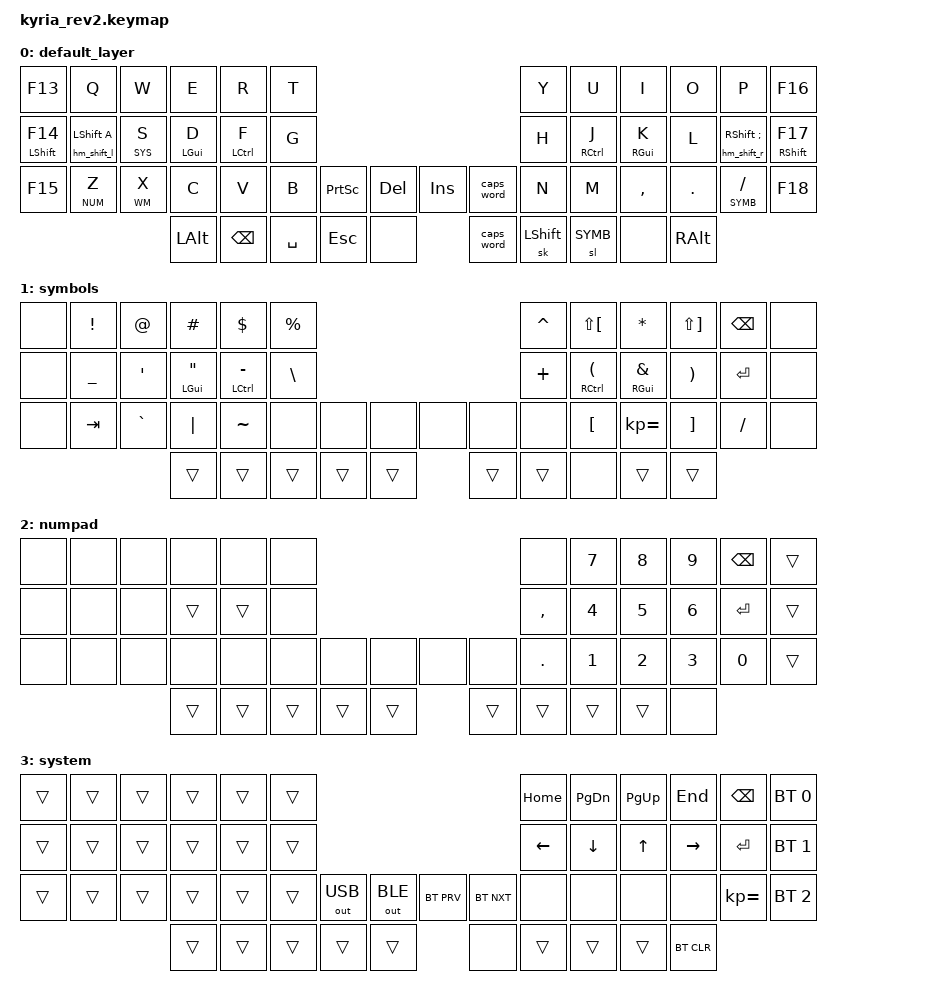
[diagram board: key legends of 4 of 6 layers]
/*
 * Copyright (c) 2020 The ZMK Contributors
 *
 * SPDX-License-Identifier: MIT
 */

#include "../zmk-nodefree-config/helper.h"
#include <behaviors.dtsi>
#include <dt-bindings/zmk/keys.h>
#include <dt-bindings/zmk/bt.h>
#include <dt-bindings/zmk/outputs.h>
#include "include/behaviours_homerow_mods.dtsi"


#define DEF 0
#define SYMB 1
#define NUM 2
#define SYS 3
#define WM 4
#define BLANK 5

&mt {
    flavor = "hold-preferred";
    tapping-term-ms = <150>;
};

&lt {
    flavor = "balanced";
    tapping-term-ms = <150>;
};

&sl {
    release-after-ms = <250>;
};

// / {
//     macros {
//         exit_symbol: exit_symbol {
//             label = "ZM_zed_em_kay";
//             compatible = "zmk,behavior-macro";
//             #binding-cells = <0>;
//             bindings = <&macro_tap &kp RETURN &to DEF>;
//         };
//         i3_1: i3_1 {
//             label = "ZM_zed_em_kay";
//             compatible = "zmk,behavior-macro";
//             #binding-cells = <0>;
//             bindings
//                 = <&macro_press &kp LGUI>
//                 , <&macro_tap &kp N1 >
//                 , <&macro_release &kp LGUI>
//                 ;
//         };
//         i3_2: i3_2 {
//             label = "ZM_zed_em_kay";
//             compatible = "zmk,behavior-macro";
//             #binding-cells = <0>;
//             bindings
//                 = <&macro_press &kp LGUI>
//                 , <&macro_tap &kp N2 >
//                 , <&macro_release &kp LGUI>
//                 ;
//         };
//         i3_3: i3_3 {
//             label = "ZM_zed_em_kay";
//             compatible = "zmk,behavior-macro";
//             #binding-cells = <0>;
//             bindings
//                 = <&macro_press &kp LGUI>
//                 , <&macro_tap &kp N3 >
//                 , <&macro_release &kp LGUI>
//                 ;
//         };
//         i3_4: i3_4 {
//             label = "ZM_zed_em_kay";
//             compatible = "zmk,behavior-macro";
//             #binding-cells = <0>;
//             bindings
//                 = <&macro_press &kp LGUI>
//                 , <&macro_tap &kp N4 >
//                 , <&macro_release &kp LGUI>
//                 ;
//         };
//         i3_5: i3_5 {
//             label = "ZM_zed_em_kay";
//             compatible = "zmk,behavior-macro";
//             #binding-cells = <0>;
//             bindings
//                 = <&macro_press &kp LGUI>
//                 , <&macro_tap &kp N5 >
//                 , <&macro_release &kp LGUI>
//                 ;
//         };
//         i3_6: i3_6 {
//             label = "ZM_zed_em_kay";
//             compatible = "zmk,behavior-macro";
//             #binding-cells = <0>;
//             bindings
//                 = <&macro_press &kp LGUI>
//                 , <&macro_tap &kp N6 >
//                 , <&macro_release &kp LGUI>
//                 ;
//         };
//         i3_7: i3_7 {
//             label = "ZM_zed_em_kay";
//             compatible = "zmk,behavior-macro";
//             #binding-cells = <0>;
//             bindings
//                 = <&macro_press &kp LGUI>
//                 , <&macro_tap &kp N7 >
//                 , <&macro_release &kp LGUI>
//                 ;
//         };
//         i3_8: i3_8 {
//             label = "ZM_zed_em_kay";
//             compatible = "zmk,behavior-macro";
//             #binding-cells = <0>;
//             bindings
//                 = <&macro_press &kp LGUI>
//                 , <&macro_tap &kp N8 >
//                 , <&macro_release &kp LGUI>
//                 ;
//         };
//         i3_9: i3_9 {
//             label = "ZM_zed_em_kay";
//             compatible = "zmk,behavior-macro";
//             #binding-cells = <0>;
//             bindings
//                 = <&macro_press &kp LGUI>
//                 , <&macro_tap &kp N9 >
//                 , <&macro_release &kp LGUI>
//                 ;
//         };
//     };
// };
//
// / {
//     combos {
//         compatible = "zmk,combos";
//         combo_caps_right {
//             timeout-ms = <50>;
//             key-positions = <20 21 22>;
//             bindings = <&caps_word>;
//         };
//         combo_caps_left {
//             timeout-ms = <50>;
//             key-positions = <14 15 16>;
//             bindings = <&caps_word>;
//         };
//         combo_i3_1 {
//             timeout-ms = <50>;
//             key-positions = <2 14>;
//             bindings = <&i3_1>;
//         };
//         combo_i3_2 {
//             timeout-ms = <50>;
//             key-positions = <3 15>;
//             bindings = <&i3_2>;
//         };
//         combo_i3_3 {
//             timeout-ms = <50>;
//             key-positions = <4 16>;
//             bindings = <&i3_3>;
//         };
//         combo_i3_4 {
//             timeout-ms = <50>;
//             key-positions = <14 26>;
//             bindings = <&i3_4>;
//         };
//         combo_i3_5 {
//             timeout-ms = <50>;
//             key-positions = <15 27>;
//             bindings = <&i3_5>;
//         };
//         combo_i3_6 {
//             timeout-ms = <50>;
//             key-positions = <16 28>;
//             bindings = <&i3_6>;
//         };
//         combo_i3_7 {
//             timeout-ms = <50>;
//             key-positions = <13 14>;
//             bindings = <&i3_7>;
//         };
//         combo_i3_8 {
//             timeout-ms = <50>;
//             key-positions = <14 15>;
//             bindings = <&i3_8>;
//         };
//         combo_i3_9 {
//             timeout-ms = <50>;
//             key-positions = <15 16>;
//             bindings = <&i3_9>;
//         };
//     };
// };

/ {
    
    

	keymap {
		compatible = "zmk,keymap";

		default_layer {
			bindings = <
&kp F13 &kp Q    &kp W    &kp E     &kp R     &kp T                                                    &kp Y      &kp U      &kp I     &kp O   &kp P    &kp F16
&mt LSHIFT F14 &hm_shift_l LSHFT A    &lt SYS S    &hm_l LGUI D    &hm_l LCTRL F     &kp G                        &kp H      &hm_r RCTRL J     &hm_r RGUI K    &kp L   &hm_shift_r RSHFT SEMI &mt RSHIFT F17
&kp F15 &lt NUM Z    &lt WM X    &kp C     &kp V     &kp B     &kp PSCRN &kp DEL        &kp INSERT &caps_word &kp N      &kp M      &kp COMMA &kp DOT &lt SYMB FSLH &kp F18
                        &kp LALT  &kp BSPC &kp SPACE &kp ESC &none       &caps_word &sk LSHIFT  &sl SYMB &none   &kp RALT
			>;
			sensor-bindings = <&inc_dec_kp C_VOL_UP C_VOL_DN &inc_dec_kp PG_UP PG_DN>;

		};

		symbols {
			bindings = <
&none &kp EXCL  &kp AT    &kp HASH &kp DOLLAR &kp PERCENT                                &kp CARET  &kp LS(LBKT) &kp STAR     &kp LS(RBKT) &kp BSPC   &none
&none &kp UNDER &kp SQT   &hm_l LGUI DQT  &hm_l LCTRL MINUS  &kp BSLH                                   &kp PLUS   &hm_r RCTRL LPAR     &hm RGUI AMPS     &kp RPAR     &kp RETURN &none
&none &kp TAB   &kp GRAVE &kp PIPE &kp TILDE  &none     &none &none     &none &none    &none      &kp LBKT     &kp KP_EQUAL &kp RBKT     &kp FSLH   &none
                          &trans    &trans      &trans   &trans &trans     &trans &trans &none &trans     &trans
			>;
			sensor-bindings = <&inc_dec_kp C_VOL_UP C_VOL_DN &inc_dec_kp PG_UP PG_DN>;
		};


		numpad {
			bindings = <
&none &none &none &none &none &none                              &none      &kp N7   &kp N8  &kp N9  &kp BSPC   &trans
&none &none &none &trans &trans &none                            &kp COMMA  &kp N4   &kp N5  &kp N6  &kp RETURN &trans
&none &none &none &none &none &none  &none &none     &none &none &kp DOT    &kp N1   &kp N2  &kp N3  &kp N0     &trans
                  &trans &trans &trans  &trans &trans     &trans &trans &trans    &trans  &none
			>;
			sensor-bindings = <&inc_dec_kp C_VOL_UP C_VOL_DN &inc_dec_kp PG_UP PG_DN>;
		};


		system {
			bindings = <
&trans  &trans &trans &trans  &trans  &trans                                                        &kp HOME   &kp PG_DN &kp PG_UP  &kp END   &kp BSPC    &bt BT_SEL 0
&trans  &trans &trans &trans  &trans  &trans                                                        &kp LEFT   &kp DOWN  &kp UP     &kp RIGHT &kp RETURN  &bt BT_SEL 1
&trans  &trans &trans &trans  &trans  &trans  &out OUT_USB  &out OUT_BLE      &bt BT_PRV  &bt BT_NXT &none     &none      &none     &none       &kp KP_EQUAL  &bt BT_SEL 2
                   &trans &trans &trans &trans        &trans     &none &trans &trans &trans     &bt BT_CLR
			>;
			sensor-bindings = <&inc_dec_kp C_VOL_UP C_VOL_DN &inc_dec_kp PG_UP PG_DN>;
		};

		wm {
			bindings = <
    &none &none &none &none &none &none                                &kp F1 &kp F2 &kp F3 &kp F4 &kp F5 &none
    &none &none &none &none &none &none                                &none &kp F19 &kp F21 &kp F22 &kp F23 &none
    &none &kp LGUI &none &kp K_COPY &kp K_PASTE &none &none &none         &kp F6 &kp F7 &kp F8 &kp F9 &kp F10 &none &none &none
                &none &none &none &none &none &none        &none &none &none &none &none &none
			>;
			sensor-bindings = <&inc_dec_kp C_VOL_UP C_VOL_DN &inc_dec_kp PG_UP PG_DN>;
		};

		blank {
			bindings = <
    &none &none &none &none &none &none                                &none &none &none &none &none &none
    &none &none &none &none &none &none                                &none &none &none &none &none &none
    &none &none &none &none &none &none &none &none        &none &none &none &none &none &none &none &none
                &none &none &none &none &none &none        &none &none &none &none &none &none
		>;
			sensor-bindings = <&inc_dec_kp C_VOL_UP C_VOL_DN &inc_dec_kp PG_UP PG_DN>;
		};

	};
};
